# a31g22x register map
Vendor: ABOV Semiconductor Co., Ltd.; Series: a31g22x; File version: 0.2
CPU: CM0PLUS r0p1, little endian, no MPU, no FPU, VTOR, 2 interrupt priority bits
Registers are 32-bit, read-write, reset 0x0 unless marked. A register's access mark holds for its fields unless they carry their own. Offsets are from the block's base; [hi:lo] are bit positions; {n}, {i} and the like mark numbered series.

## ADC — 12-BIT A/D CONVERTER
Base 0x40003100
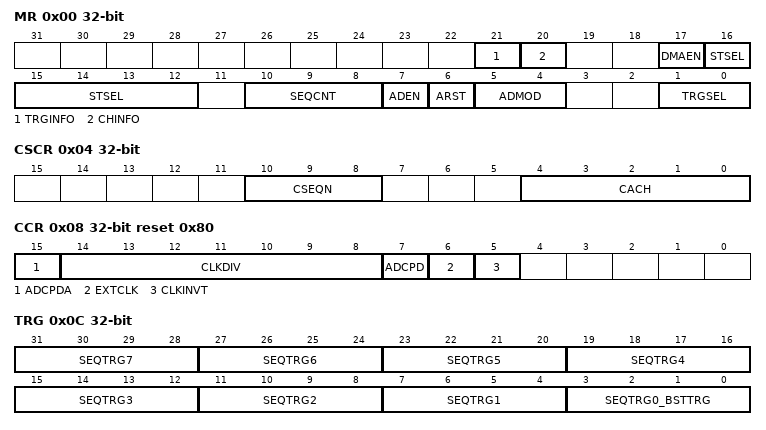
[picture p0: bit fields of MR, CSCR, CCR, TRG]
0x00 MR — ADC Mode Register
  [21] TRGINFO — Trigger Information Option (In external trigger mode)
  [20] CHINFO — Channel Information Option
  [17] DMAEN — DMA Enable Bit (only ADCEN=1)
    0=Disable (DMA Disable); 1=Enable (DMA Enable)
  [16:12] STSEL — Sampling Time Selection
  [10:8] SEQCNT — Number of conversion in a sequence
    0=SEQ1 (Single Mode); {v}=SEQ{v+1} ({v+1} Sequence ADC) (v=1..7)
  [7] ADEN — ADC Enable Bit
    0=Disable ADC; 1=Enable ADC
  [6] ARST — When sequence is over, restart control bit
    0=STOP (after ending, STOP); 1=RESTART (After ending, restart)
  [5:4] ADMOD — ADC Mode Selection Bit
    0=Single_Sequencial Conversion Mode; 1=Burst Conversion Mode; 2=Multiple Conversion Mode
  [1:0] TRGSEL — Trigger Selection Bit
    0=Soft_TRG (Software Trigger Only); 1=TIMER1n event trigger; 2=TIMER30 (TIMER30 event trigger)
0x04 CSCR — ADC Current Sequence_Channel Register
  [10:8] CSEQN — Current Sequence Number
    {v}=Sequence{v} (Current Sequence {v}) (v=0..7)
  [4:0] CACH ro — Current Active Channel
    {v}=CH{v} (ADC Channel active is {v}) (v=0..17)
0x08 CCR reset 0x80 — ADC Clock Control Register
  [15] ADCPDA — ADC disablement for power saving
    0=NORMAL (ADC Normal Mode); 1=LOWPOWER (ADC low power mode @ low speed operation)
  [14:8] CLKDIV — ADC Clock Divider value bit, ADC CLK = ADC Input Clock / CLKDIV (CLKDIV=1 ADC Stop, CLKDIV=0 ADC Input Clock)
  [7] ADCPD — ADC Deep Sleep
    0=NORMAL (ADC Normal Mode); 1=LOWPOWER (ADC Deep Sleep Mode)
  [6] EXTCLK — ADC External Clock Setting Bit
    0=Internal (ADC Internal Clock (CLKDIV Enable)); 1=External (ADC External Clock (SCU Clock))
  [5] CLKINVT — Divide Clock Inversion (Option bit)
    0=Larger_50 (duty ratio of divided clock is larger than 50p); 1=Less_50 (duty ratio of divided clock is less than 50p)
0x0C TRG — ADC Trigger Selection Register
  [all] fields
    {v}=TRGSRC{v} (Source {v}) (v=0..9); 15=TRGSRC15 (Source 15)
  [4n+3:4n] SEQTRG{n} (n=1..7) — Sequence Trigger Source {n+1}th
  [3:0] SEQTRG0_BSTTRG — Sequence Trigger Source 1th, Burst Conversion Trigger Source
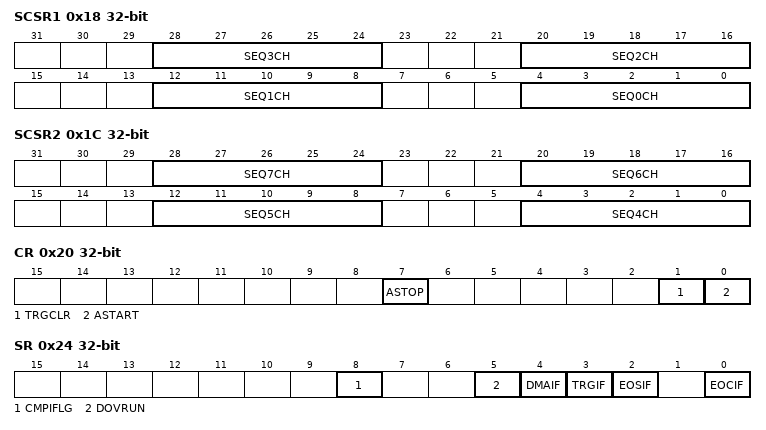
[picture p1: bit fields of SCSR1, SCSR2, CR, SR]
0x18 SCSR1 — ADC Channel Selection Register 1
  [8n+4:8n] SEQ{n}CH (n=0..3) — Conversion Sequence Channel Selection {n+1}th
0x1C SCSR2 — ADC Channel Selection Register 2
  [8n-28:8n-32] SEQ{n}CH (n=4..7) — Conversion Sequence Channel Selection {n+1}th
0x20 CR — ADC Control Register
  [7] ASTOP wo — ADC STOP bit
  [1] TRGCLR — ADC all trigger flags cleared option (previous ADC operation)
  [0] ASTART — ADC START Bit
0x24 SR (reset mask 0xFF) — ADC Status Register
  [8] CMPIFLG — Compare Interrupt Flag Bit
  [5] DOVRUN — DMA Overrun Flag (Not Interrupt)
  [4] DMAIF — DMA Done Interrupt Flag (DMA transfer is completed)
  [3] TRGIF — ADC Trigger Interrupt Flag (Write '1' to clear flag)
  [2] EOSIF — Sequence End Interrupt Flag (Write '1' to clear flag)
  [0] EOCIF — Sequence Conversion End Interrupt Flag (Write '1' to clear flag)
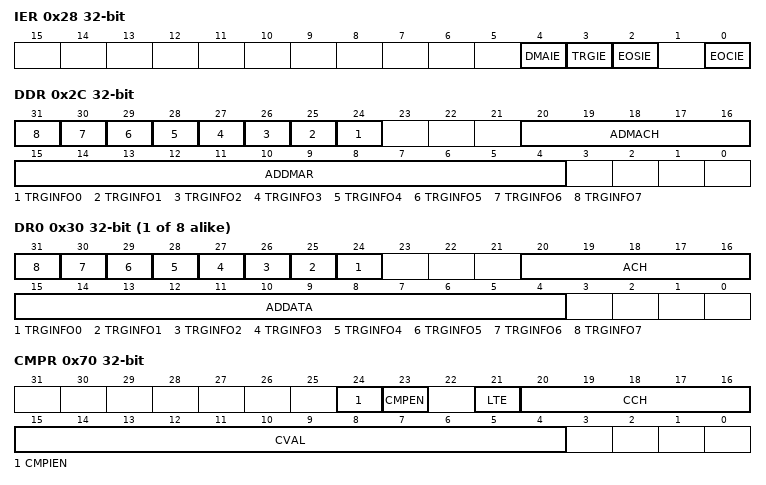
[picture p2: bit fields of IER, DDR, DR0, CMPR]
0x28 IER — ADC Interrupt Enable Register
  [4] DMAIE — DMA Done Interrupt Enable
    0=Disable (DMA Interrupt Disable); 1=Enable (DMA Interrupt Enable)
  [3] TRGIE — ADC Trigger Conversion Interrupt Enable
    0=Disable (ADC Trigger Conversion Interrupt Disable); 1=Enable (ADC Trigger Conversion Interrupt Enable)
  [2] EOSIE — ADC Sequence Conversion Interrupt Enable
    0=Disable (ADC Sequence Conversion Interrupt Disable); 1=Enable (ADC Sequence Conversion Interrupt Enable)
  [0] EOCIE — ADC Single Conversion Interrupt Enable
    0=Disable (ADC Single Conversion Interrupt Disable); 1=Enable (ADC Single Conversion Interrupt Enable)
0x2C DDR ro (reset mask 0xFFFF) — ADC DMA Data Register
  [n+24] TRGINFO{n} (n=0..7) — ADC Trigger Information
  [20:16] ADMACH — ADC Data Channel Indicator
  [15:4] ADDMAR — ADC Conversion Result Data (12-bit)
{0x30+4i} DR{i} (i=0..7) — ADC Sequence Data Register{i}
  [n+24] TRGINFO{n} ro (n=0..7) — ADC Trigger Information
  [20:16] ACH ro — ADC Channel Information
  [15:4] ADDATA ro — ADC Channel Data (12-bit)
0x70 CMPR — ADC Channel Compare Register
  [24] CMPIEN — Compare Interrupt Enable Bit
    0=Disable (Compare Disable); 1=Enable (Compare Enable)
  [23] CMPEN — Compare Operation Enable Bit
    0=Disable (Compare Disable); 1=Enable (Compare Enable)
  [21] LTE — AD Conversion Value Output Timing Setting
    0=OUTPUT1 (If ADC value is higher than CVAL value, output.); 1=OUTPUT2 (If the ADC value is lower than the CVAL value, it is output.)
  [20:16] CCH — Compare Channel
    {v}=CH{v} (ADC Channel {v}) (v=0..17)
  [15:4] CVAL — Compare Value
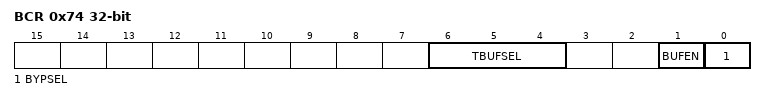
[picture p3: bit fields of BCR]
0x74 BCR reset not defined — ADC Buffer Control Register
  [6:4] TBUFSEL — Buffering Off Time Selection Bit 0: 1*MCLK 1: 2*MCLK 2: 3*MCLK 3: 4*MCLK 4: 5*MCLK 5: 6*MCLK 6: 7*MCLK 7: 8*MCLK
  [1] BUFEN — ADC Input Buffer Enable Bit 0: Input Buffer Power Dcown Period 1: Input Buffer Operation Period
  [0] BYPSEL — ADC Input Buffer Bypass Selection Bit 0: Input Buffer Operation mode. 1: Input Buffer Bypass Mode.
